AUTOSAR XML (schema 4-2-2)
package /ComponentTypes
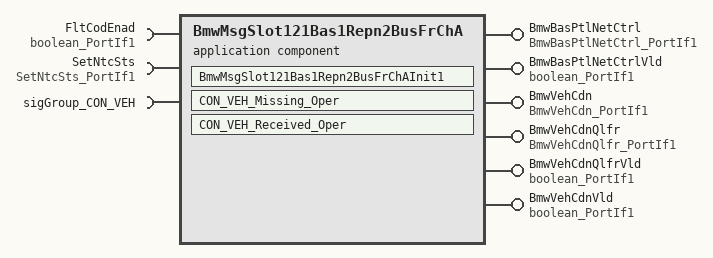
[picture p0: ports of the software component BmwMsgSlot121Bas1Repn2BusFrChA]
  application sw component type BmwMsgSlot121Bas1Repn2BusFrChA
    6 x provide port:
      BmwBasPtlNetCtrl: nonqueued-sender-com-spec{data-element=Val, init-value=15}, provided-interface=BmwBasPtlNetCtrl_PortIf1
      BmwBasPtlNetCtrlVld: nonqueued-sender-com-spec{data-element=Logl, init-value=0}, provided-interface=boolean_PortIf1
      BmwVehCdn: nonqueued-sender-com-spec{data-element=Val, init-value=15}, provided-interface=BmwVehCdn_PortIf1
      BmwVehCdnQlfr: nonqueued-sender-com-spec{data-element=Val, init-value=15}, provided-interface=BmwVehCdnQlfr_PortIf1
      BmwVehCdnQlfrVld: nonqueued-sender-com-spec{data-element=Logl, init-value=0}, provided-interface=boolean_PortIf1
      BmwVehCdnVld: nonqueued-sender-com-spec{data-element=Logl, init-value=0}, provided-interface=boolean_PortIf1
    require port FltCodEnad: nonqueued-receiver-com-spec{data-element=Logl, filter=data-filter-type=ALWAYS, init-value=1}, required-interface=boolean_PortIf1
    require port SetNtcSts: client-com-spec=Oper, required-interface=SetNtcSts_PortIf1
    require port sigGroup_CON_VEH: nonqueued-receiver-com-spec{data-element=sigGroup_CON_VEH, uses-end-to-end-protection=true, alive-timeout=0.11, enable-update=true, filter=data-filter-type=ALWAYS, init-value=fields=[CTR_FKTN_PRTNT:0, QU_ST_CON_VEH:15, CRC_CON_VEH:0, ST_CON_VEH:15, CTR_BS_PRTNT:15, ALIV_CON_VEH:0, CON_VEH_dummy_56_63:0]}, required-interface=sigGroup_CON_VEH
    behavior BmwMsgSlot121Bas1Repn2BusFrChA_InternalBehavior
      ar-typed-per-instance-memorys:
        23 x data, all with sw-calibration-access=READ-ONLY:
          AlvFaildCnt: type=uint8
          AlvPassdCnt: type=uint8
          BmwBasPtlNetCtrlPrev: type=BmwBasPtlNetCtrl1
          BmwVehCdnPrev: type=BmwVehCdn1
          BmwVehCdnQlfrPrev: type=BmwVehCdnQlfr1
          CrcFaildCnt: type=uint8
          CrcPassdCnt: type=uint8
          CtrBsPrtntFaildCnt: type=uint8
          CtrBsPrtntPassdCnt: type=uint8
          CtrFktnPrtntFaildCnt: type=uint8
          CtrFktnPrtntPassdCnt: type=uint8
          Dummy_PIM1: type=QU_ST_CON_VEH1
          Dummy_PIM2: type=QU_V_VEH_COG1
          Dummy_PIM3: type=ST_CON_VEH1
          Dummy_PIM4: type=CTR_BS_PRTNT1
          MissMsgCnt: type=uint8
          QlfrCogFaildCnt: type=uint8
          QlfrCogPassdCnt: type=uint8
          QuStConVehFaildCnt: type=uint8
          QuStConVehPassdCnt: type=uint8
          RxdMsgCnt: type=uint8
          StConVehFaildCnt: type=uint8
          StConVehPassdCnt: type=uint8
      init event BmwMsgSlot121Bas1Repn2BusFrChAInit1_InitEvent: start-on-event=BmwMsgSlot121Bas1Repn2BusFrChAInit1
      data receive error event DRET_CON_VEH_Missing_Oper_sigGroup_CON_VEH_sigGroup_CON_VEH: start-on-event=CON_VEH_Missing_Oper, data=sigGroup_CON_VEH.sigGroup_CON_VEH
      data received event DRT_CON_VEH_Received_Oper_sigGroup_CON_VEH_sigGroup_CON_VEH: start-on-event=CON_VEH_Received_Oper, data=sigGroup_CON_VEH.sigGroup_CON_VEH
      port-api-options:
        enable-take-address=false, error-handling=NO-TRANSFORMER-ERROR-HANDLING, indirect-api=false, port=BmwBasPtlNetCtrl
        enable-take-address=false, error-handling=NO-TRANSFORMER-ERROR-HANDLING, indirect-api=false, port=BmwBasPtlNetCtrlVld
        enable-take-address=false, error-handling=NO-TRANSFORMER-ERROR-HANDLING, indirect-api=false, port=BmwVehCdn
        enable-take-address=false, error-handling=NO-TRANSFORMER-ERROR-HANDLING, indirect-api=false, port=BmwVehCdnQlfr
        enable-take-address=false, error-handling=NO-TRANSFORMER-ERROR-HANDLING, indirect-api=false, port=BmwVehCdnQlfrVld
        enable-take-address=false, error-handling=NO-TRANSFORMER-ERROR-HANDLING, indirect-api=false, port=BmwVehCdnVld
        enable-take-address=false, error-handling=NO-TRANSFORMER-ERROR-HANDLING, indirect-api=false, port=FltCodEnad
        enable-take-address=false, error-handling=NO-TRANSFORMER-ERROR-HANDLING, indirect-api=false, port=SetNtcSts
        enable-take-address=false, error-handling=NO-TRANSFORMER-ERROR-HANDLING, indirect-api=false, port=sigGroup_CON_VEH
      runnable BmwMsgSlot121Bas1Repn2BusFrChAInit1
        data-receive-point-by-arguments:
          access REC_FltCodEnad_Logl: accessed-variable=FltCodEnad.Logl
        data-send-points:
          6 x access:
            SEND_BmwActIntgtdCtrlModlPosnIdxValVld_Logl: accessed-variable=BmwVehCdnQlfrVld.Logl
            SEND_BmwBasPtlNetCtrl_Val: accessed-variable=BmwBasPtlNetCtrl.Val
            SEND_BmwQuadOffsStsVld_Logl: accessed-variable=BmwVehCdnVld.Logl
            SEND_BmwQuadRtrOffsVld_Logl: accessed-variable=BmwBasPtlNetCtrlVld.Logl
            SEND_BmwVehCdn_Val: accessed-variable=BmwVehCdn.Val
            SEND_BmwVehCdnQlfr_Val: accessed-variable=BmwVehCdnQlfr.Val
        sync call SC_SetNtcSts_Oper: operation=SetNtcSts.Oper, timeout=0
      runnable CON_VEH_Missing_Oper
        data-receive-point-by-arguments:
          access REC_FltCodEnad_Logl: accessed-variable=FltCodEnad.Logl
        data-send-points:
          6 x access:
            SEND_BmwBasPtlNetCtrl_Val: accessed-variable=BmwBasPtlNetCtrl.Val
            SEND_BmwBasPtlNetCtrlVld_Logl: accessed-variable=BmwBasPtlNetCtrlVld.Logl
            SEND_BmwVehCdn_Val: accessed-variable=BmwVehCdn.Val
            SEND_BmwVehCdnQlfr_Val: accessed-variable=BmwVehCdnQlfr.Val
            SEND_BmwVehCdnQlfrVld_Logl: accessed-variable=BmwVehCdnQlfrVld.Logl
            SEND_BmwVehCdnVld_Logl: accessed-variable=BmwVehCdnVld.Logl
        sync call SC_SetNtcSts_Oper: operation=SetNtcSts.Oper, timeout=0
      runnable CON_VEH_Received_Oper
        data-receive-point-by-arguments:
          access REC_FltCodEnad_Logl: accessed-variable=FltCodEnad.Logl
          access REC_sigGroup_CON_VEH_sigGroup_CON_VEH: accessed-variable=sigGroup_CON_VEH.sigGroup_CON_VEH
        data-send-points:
          6 x access:
            SEND_BmwBasPtlNetCtrl_Val: accessed-variable=BmwBasPtlNetCtrl.Val
            SEND_BmwBasPtlNetCtrlVld_Logl: accessed-variable=BmwBasPtlNetCtrlVld.Logl
            SEND_BmwVehCdn_Val: accessed-variable=BmwVehCdn.Val
            SEND_BmwVehCdnQlfr_Val: accessed-variable=BmwVehCdnQlfr.Val
            SEND_BmwVehCdnQlfrVld_Logl: accessed-variable=BmwVehCdnQlfrVld.Logl
            SEND_BmwVehCdnVld_Logl: accessed-variable=BmwVehCdnVld.Logl
        sync call SC_SetNtcSts_Oper: operation=SetNtcSts.Oper, timeout=0
  swc implementation BmwMsgSlot121Bas1Repn2BusFrChA_Implementation: behavior=BmwMsgSlot121Bas1Repn2BusFrChA_InternalBehavior
    code-descriptors:
      code Default: artifact-descriptors=autosar-engineering-object={short-label=Default, category=SWSRC}
